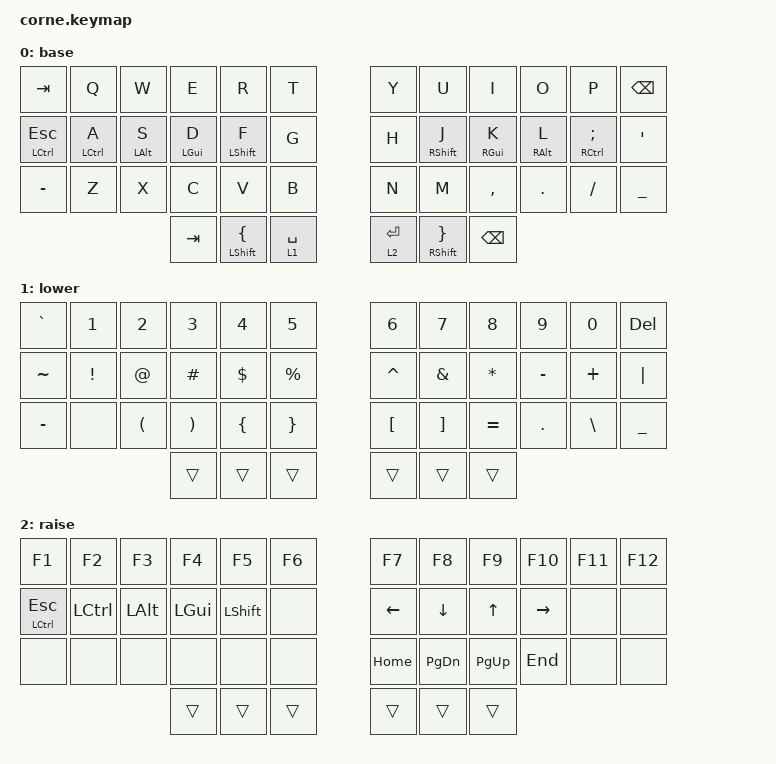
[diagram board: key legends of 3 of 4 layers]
/*
 * Copyright (c) 2020 The ZMK Contributors
 *
 * SPDX-License-Identifier: MIT
 */

#include <behaviors.dtsi>
#include <dt-bindings/zmk/bt.h>
#include <dt-bindings/zmk/keys.h>
#include "../../zmk-nodefree-config/keypos_def/keypos_36keys.h"
#include "../../zmk-nodefree-config/helper.h"

/* Bluetooth */
#define _BT_SEL_KEYS_ &bt BT_SEL 0 &bt BT_SEL 1 &bt BT_SEL 2 &bt BT_SEL 3 &bt BT_SEL 4

/* Layers */
#define BASE    0
#define LOWER   1
#define RAISE   2
#define TRI     3

/* Homerow mods */
/ {

#define TAP_TERM_MS             270
#define QUICK_TAP_MS            300
#define REQUIRE_PRIOR_IDLE_MS   250

#define INDEX_TAP_TERM_MS               170
#define INDEX_QUICK_TAP_MS              300
#define INDEX_REQUIRE_PRIOR_IDLE_MS     150

#define KEYS_LEFT LT0 LT1 LT2 LT3 LT4 LM0 LM1 LM2 LM3 LM4 LB0 LB1 LB2 LB3 LB4  // left hand
#define KEYS_RIGHT RT0 RT1 RT2 RT3 RT4 RM0 RM1 RM2 RM3 RM4 RB0 RB1 RB2 RB3 RB4  // right hand
#define THUMBS LH2 LH1 LH0 RH0 RH1 RH2                                      // thumbs

behaviors {
    // For the "layer" key, it'd nice to be able to use it as either a shift or a toggle.
    // Configure it as a tap dance, so the first tap (or hold) is a &mo and the second tap is a &to

    hml: hold_tap_left {
        compatible = "zmk,behavior-hold-tap";
        label = "HRM_HOLD_TAP_LEFT";
        flavor = "tap-preferred";
        tapping-term-ms = <TAP_TERM_MS>;
        quick-tap-ms = <QUICK_TAP_MS>;
        require-prior-idle-ms = <REQUIRE_PRIOR_IDLE_MS>;
        #binding-cells = <2>;
        bindings = <&kp>, <&kp>;

        hold-trigger-key-positions = <KEYS_RIGHT THUMBS>;
        hold-trigger-on-release;
    };

    hmli: hold_tap_left_index {
        compatible = "zmk,behavior-hold-tap";
        label = "HRM_HOLD_TAP_LEFT_INDEX";
        flavor = "tap-preferred";
        tapping-term-ms = <INDEX_TAP_TERM_MS>;
        quick-tap-ms = <INDEX_QUICK_TAP_MS>;
        require-prior-idle-ms = <INDEX_REQUIRE_PRIOR_IDLE_MS>;
        #binding-cells = <2>;
        bindings = <&kp>, <&kp>;

        hold-trigger-key-positions = <KEYS_RIGHT THUMBS>;
        hold-trigger-on-release;
    };

    hmr: hold_tap_right {
        compatible = "zmk,behavior-hold-tap";
        label = "HRM_HOLD_TAP_RIGHT";
        flavor = "tap-preferred";
        tapping-term-ms = <TAP_TERM_MS>;
        quick-tap-ms = <QUICK_TAP_MS>;
        require-prior-idle-ms = <REQUIRE_PRIOR_IDLE_MS>;
        #binding-cells = <2>;
        bindings = <&kp>, <&kp>;

        hold-trigger-key-positions = <KEYS_LEFT THUMBS>;
        hold-trigger-on-release;
    };

    hmri: hold_tap_right_index {
        compatible = "zmk,behavior-hold-tap";
        label = "HRM_HOLD_TAP_RIGHT_INDEX";
        flavor = "tap-preferred";
        tapping-term-ms = <INDEX_TAP_TERM_MS>;
        quick-tap-ms = <INDEX_QUICK_TAP_MS>;
        require-prior-idle-ms = <INDEX_REQUIRE_PRIOR_IDLE_MS>;
        #binding-cells = <2>;
        bindings = <&kp>, <&kp>;

        hold-trigger-key-positions = <KEYS_LEFT THUMBS>;
        hold-trigger-on-release;
    };

    qt: quick_tap {
        compatible = "zmk,behavior-hold-tap";
        label = "QUICK_TAP";
        flavor = "balanced";
        tapping-term-ms = <200>;
        quick-tap-ms = <175>;
        require-prior-idle-ms = <150>;
        #binding-cells = <2>;
        bindings = <&kp>, <&kp>;

        hold-trigger-on-release;
    };    
};

#define _CTRL_ESC_      &mt LCTRL ESC
#define _HOME_A_        &hml LCTRL A
#define _HOME_S_        &hml LALT S
#define _HOME_D_        &hml LGUI D
#define _HOME_F_        &hmli LSHFT F

#define _HOME_J_        &hmri RSHFT J
#define _HOME_K_        &hmr RGUI K
#define _HOME_L_        &hmr RALT L
#define _HOME_SEMI_     &hmr RCTRL SEMI


#define _THUMB_LH0_     &lt 1 SPACE
#define _THUMB_LH1_     &hml LSHFT LBRC
#define _THUMB_LH2_     &kp TAB

#define _THUMB_RH0_     &lt 2 ENTER
#define _THUMB_RH1_     &hmr RSHFT RBRC
#define _THUMB_RH2_     &kp BSPC

#define _MAC_LOCK_      &kp RG(RC(Q))
#define _SCRN_CAP_      &kp RG(RS(N4))
#define _ZOOM_IN_       &kp RG(RS(EQUAL))
#define _ZOOM_OUT_      &kp RG(MINUS)
};

ZMK_CONDITIONAL_LAYER(LOWER RAISE, TRI)

ZMK_LAYER(base,
//╭──────────────┬──────────────┬──────────────┬──────────────┬──────────────┬──────────────╮ ╭──────╮ ╭──────────────┬──────────────┬──────────────┬──────────────┬──────────────┬──────────────╮
    &kp TAB        &kp Q          &kp W          &kp E          &kp R          &kp T                     &kp Y          &kp U          &kp I          &kp O          &kp P          &kp BSPC
//├──────────────┼──────────────┼──────────────┼──────────────┼──────────────┼──────────────┤ ├──────┤ ├──────────────┼──────────────┼──────────────┼──────────────┼──────────────┼──────────────┤
    _CTRL_ESC_     _HOME_A_       _HOME_S_       _HOME_D_       _HOME_F_       &kp G                     &kp H          _HOME_J_       _HOME_K_       _HOME_L_       _HOME_SEMI_    &kp SQT
//├──────────────┼──────────────┼──────────────┼──────────────┼──────────────┼──────────────┤ ├──────┤ ├──────────────┼──────────────┼──────────────┼──────────────┼──────────────┼──────────────┤
    &kp MINUS      &kp Z          &kp X          &kp C          &kp V          &kp B                     &kp N          &kp M          &kp COMMA      &kp DOT        &kp FSLH       &kp UNDER
//├──────────────┼──────────────┼──────────────┼──────────────┼──────────────┼──────────────┤ ├──────┤ ├──────────────┼──────────────┼──────────────┼──────────────┼──────────────┼──────────────┤
                                                 _THUMB_LH2_    _THUMB_LH1_    _THUMB_LH0_               _THUMB_RH0_    _THUMB_RH1_    _THUMB_RH2_
//                                             ╰──────────────┴──────────────┴──────────────╯ ╰──────╯ ╰──────────────┴──────────────┴──────────────╯
)

ZMK_LAYER(lower,
//╭──────────────┬──────────────┬──────────────┬──────────────┬──────────────┬──────────────╮ ╭──────╮ ╭──────────────┬──────────────┬──────────────┬──────────────┬──────────────┬──────────────╮
    &kp GRAVE      &kp N1         &kp N2         &kp N3         &kp N4         &kp N5                    &kp N6         &kp N7         &kp N8         &kp N9         &kp N0         &kp DEL
//├──────────────┼──────────────┼──────────────┼──────────────┼──────────────┼──────────────┤ ├──────┤ ├──────────────┼──────────────┼──────────────┼──────────────┼──────────────┼──────────────┤
    &kp TILDE      &kp EXCL       &kp AT         &kp HASH       &kp DLLR       &kp PRCNT                 &kp CARET      &kp AMPS       &kp STAR       &kp MINUS      &kp PLUS       &kp PIPE
//├──────────────┼──────────────┼──────────────┼──────────────┼──────────────┼──────────────┤ ├──────┤ ├──────────────┼──────────────┼──────────────┼──────────────┼──────────────┼──────────────┤
    &kp MINUS      &none          &kp LPAR       &kp RPAR       &kp LBRC       &kp RBRC                  &kp LBKT       &kp RBKT       &kp EQUAL      &kp DOT        &kp BSLH       &kp UNDER
//├──────────────┼──────────────┼──────────────┼──────────────┼──────────────┼──────────────┤ ├──────┤ ├──────────────┼──────────────┼──────────────┼──────────────┼──────────────┼──────────────┤
                                                 &trans         &trans         &trans                    &trans         &trans         &trans
//                                             ╰──────────────┴──────────────┴──────────────╯ ╰──────╯ ╰──────────────┴──────────────┴──────────────╯
)

ZMK_LAYER(raise,
//╭──────────────┬──────────────┬──────────────┬──────────────┬──────────────┬──────────────╮ ╭──────╮ ╭──────────────┬──────────────┬──────────────┬──────────────┬──────────────┬──────────────╮
    &kp F1         &kp F2         &kp F3         &kp F4         &kp F5         &kp F6                    &kp F7         &kp F8         &kp F9         &kp F10        &kp F11         &kp F12
//├──────────────┼──────────────┼──────────────┼──────────────┼──────────────┼──────────────┤ ├──────┤ ├──────────────┼──────────────┼──────────────┼──────────────┼──────────────┼──────────────┤
    _CTRL_ESC_     &kp LCTRL      &kp LALT       &kp LGUI       &kp LSHFT      &none                     &kp LEFT       &kp DOWN       &kp UP         &kp RIGHT      &none           &none
//├──────────────┼──────────────┼──────────────┼──────────────┼──────────────┼──────────────┤ ├──────┤ ├──────────────┼──────────────┼──────────────┼──────────────┼──────────────┼──────────────┤
    &none          &none          &none          &none          &none          &none                     &kp HOME       &kp PG_DN      &kp PG_UP      &kp END        &none           &none
//├──────────────┼──────────────┼──────────────┼──────────────┼──────────────┼──────────────┤ ├──────┤ ├──────────────┼──────────────┼──────────────┼──────────────┼──────────────┼──────────────┤
                                                 &trans         &trans         &trans                    &trans         &trans         &trans
//                                             ╰──────────────┴──────────────┴──────────────╯ ╰──────╯ ╰──────────────┴──────────────┴──────────────╯
)

ZMK_LAYER(tri,
//╭──────────────┬──────────────┬──────────────┬──────────────┬──────────────┬──────────────╮ ╭──────╮ ╭──────────────┬──────────────┬──────────────┬──────────────┬──────────────┬──────────────╮
    &none          &none          &none          &none          &none          &none                     &kp C_PREV     &kp C_NEXT     &none          &none          &none          &bt BT_CLR
//├──────────────┼──────────────┼──────────────┼──────────────┼──────────────┼──────────────┤ ├──────┤ ├──────────────┼──────────────┼──────────────┼──────────────┼──────────────┼──────────────┤
    &none          &none          &none          &none          &none          &none                     &kp C_VOL_DN   &kp C_VOL_UP   &none          &none          _ZOOM_IN_      _SCRN_CAP_
//├──────────────┼──────────────┼──────────────┼──────────────┼──────────────┼──────────────┤ ├──────┤ ├──────────────┼──────────────┼──────────────┼──────────────┼──────────────┼──────────────┤
    &none                                   _BT_SEL_KEYS_                                                &kp C_PLAY     &none          &none          &none          _ZOOM_OUT_     _MAC_LOCK_
//├──────────────┼──────────────┼──────────────┼──────────────┼──────────────┼──────────────┤ ├──────┤ ├──────────────┼──────────────┼──────────────┼──────────────┼──────────────┼──────────────┤
                                                 &trans         &trans         &trans                    &trans         &trans         &trans
//                                             ╰──────────────┴──────────────┴──────────────╯ ╰──────╯ ╰──────────────┴──────────────┴──────────────╯
)
